# CY8C3246PVI_147 register map
File version: 0.1
CY8C32
Registers are 8-bit, read-write, no defined reset value unless marked. A register's access mark holds for its fields unless they carry their own. Offsets are from the block's base; lines under a group give offsets from that group; [hi:lo] are bit positions; {n}, {i} and the like mark numbered series; 'fields as' and 'values as' point back to an identical list; <NAME> marks a mode.

## Memory map
0x00000000 MY_TIMER
0x00000000 LED_BLINK
0x00000000 WATCHDOG_COUNTER
0x00000000 PACER_TIMER
0x00000000 UART_RS485 — UART
0x00000000 PWM_MOTORS
0x00000000 ADC
0x00000000 COUNTER_ENC
0x00006460 ADC_STATUS
0x00006465 FF_STATUS
0x00006470 LED_CTRL
0x00006471 LED_BLINK_EN
0x00006472 RESET_COUNTERS
0x00006474 ADC_SOC
0x00006475 RESET_FF
0x00006477 WATCHDOG_ENABLER
0x00006478 MOTOR_DIR
0x0000647E FTDI_ENABLE_REG
0x00006577 WATCHDOG_REFRESH
0x00006579 RS485_CTS
0x0000657B MOTOR_ON_OFF

## MY_TIMER
Base 0x00000000
0x6404 MY_TIMER_COUNTER 24-bit — UDB.A0 - Current Down Counter Value
0x6424 MY_TIMER_PERIOD 24-bit — UDB.D0 - Assigned Period
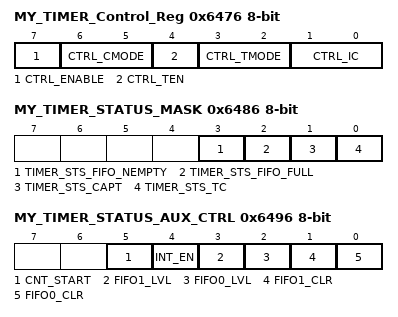
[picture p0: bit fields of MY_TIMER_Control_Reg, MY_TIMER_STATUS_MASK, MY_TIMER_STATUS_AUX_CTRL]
0x6476 MY_TIMER_Control_Reg — UDB Control Register - Assigned Control Register Value
  [7] CTRL_ENABLE — Enable the Timer
  [6:5] CTRL_CMODE — Capture Mode
  [4] CTRL_TEN — Trigger Enable Bit
  [3:2] CTRL_TMODE — Trigger Mode
  [1:0] CTRL_IC — Interrupt Count
0x6486 MY_TIMER_STATUS_MASK — UDB Status bits Interrupt Mask Enable Register
  [3] TIMER_STS_FIFO_NEMPTY ro — FIFO Empty status
  [2] TIMER_STS_FIFO_FULL ro — FIFO Full Status
  [1] TIMER_STS_CAPT ro — Enables the Interrupt on Capture
  [0] TIMER_STS_TC ro — Enables the Interrupt on TC
0x6496 MY_TIMER_STATUS_AUX_CTRL — UDB Auxilliary Control Register
  [5] CNT_START — FIFO0 clear
    0=E_CNT_START0 (Disable counter); 1=E_CNT_START1 (Enable counter)
  [4] INT_EN
    0=E_INT_EN0 (Interrupt disabled); 1=E_INT_EN1 (Interrupt enabled)
  [3] FIFO1_LVL — FIFO level
    0=E_FIFO_LVL_0 (FIFO LVL: input mode: FIFO not full; output mode: FIFO not empty); 1=E_FIFO_LVL_1 (FIFO LVL: input mode: FIFO at least 1/2 empty; output mode: FIFO at least 1/2 full)
  [2] FIFO0_LVL — FIFO level
    values as FIFO1_LVL
  [1] FIFO1_CLR — FIFO1 clear
    0=E_FIFO_CLR_0 (Normal FIFO operation); 1=E_FIFO_CLR_1 (Clear FIFO state)
  [0] FIFO0_CLR — FIFO0 clear
    values as FIFO1_CLR

## ADC_STATUS
Base 0x00006460
0x00 ADC_STATUS_STATUS_REG
0x20 ADC_STATUS_MASK_REG
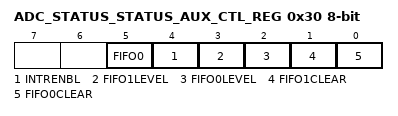
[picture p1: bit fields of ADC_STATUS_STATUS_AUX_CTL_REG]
0x30 ADC_STATUS_STATUS_AUX_CTL_REG
  [5] FIFO0 — FIFO0 clear
    1=ENABLED (Enable counter); 0=DISABLED (Disable counter)
  [4] INTRENBL — Enables or disables the Interrupt
    1=ENABLED (Interrupt enabled); 0=DISABLED (Interrupt disabled)
  [3] FIFO1LEVEL — FIFO level
    1=ENABLED (FIFO LVL: input mode: FIFO at least 1/2 empty; output mode: FIFO at least 1/2 full); 0=DISABLED (FIFO LVL: input mode: FIFO not full; output mode: FIFO not empty)
  [2] FIFO0LEVEL — FIFO level
    values as FIFO1LEVEL
  [1] FIFO1CLEAR — FIFO clear
    1=ENABLED (Clear FIFO state); 0=DISABLED (Normal FIFO operation)
  [0] FIFO0CLEAR — FIFO clear
    values as FIFO1CLEAR

## FF_STATUS
Base 0x00006465
Registers as ADC_STATUS (with ADC_STATUS read as FF_STATUS).

## RESET_COUNTERS
Base 0x00006472
0x00 RESET_COUNTERS_CONTROL_REG

## FTDI_ENABLE_REG
Base 0x0000647E
Registers as RESET_COUNTERS (with RESET_COUNTERS read as FTDI_ENABLE_REG).

## RESET_FF
Base 0x00006475
Registers as RESET_COUNTERS (with RESET_COUNTERS read as RESET_FF).

## ADC_SOC
Base 0x00006474
Registers as RESET_COUNTERS (with RESET_COUNTERS read as ADC_SOC).

## WATCHDOG_REFRESH
Base 0x00006577
Registers as RESET_COUNTERS (with RESET_COUNTERS read as WATCHDOG_REFRESH).

## WATCHDOG_ENABLER
Base 0x00006477
Registers as RESET_COUNTERS (with RESET_COUNTERS read as WATCHDOG_ENABLER).

## LED_CTRL
Base 0x00006470
Registers as RESET_COUNTERS (with RESET_COUNTERS read as LED_CTRL).

## LED_BLINK_EN
Base 0x00006471
Registers as RESET_COUNTERS (with RESET_COUNTERS read as LED_BLINK_EN).

## MOTOR_DIR
Base 0x00006478
Registers as RESET_COUNTERS (with RESET_COUNTERS read as MOTOR_DIR).

## MOTOR_ON_OFF
Base 0x0000657B
Registers as RESET_COUNTERS (with RESET_COUNTERS read as MOTOR_ON_OFF).

## RS485_CTS
Base 0x00006579
Registers as RESET_COUNTERS (with RESET_COUNTERS read as RS485_CTS).
